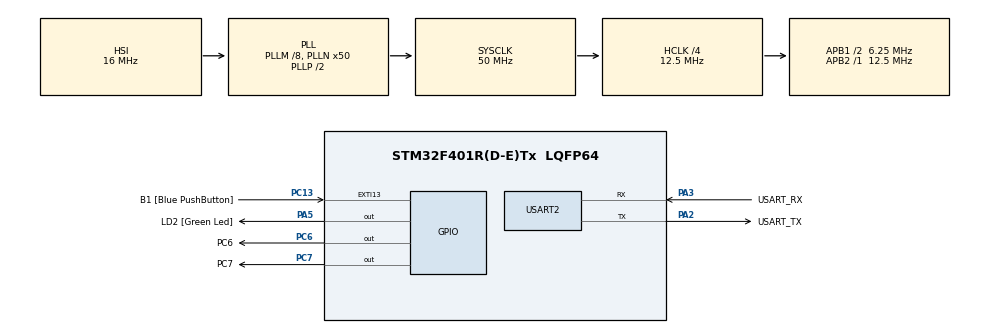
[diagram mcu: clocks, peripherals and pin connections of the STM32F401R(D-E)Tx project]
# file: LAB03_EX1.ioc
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Mcu.Family=STM32F4
Mcu.Name=STM32F401R(D-E)Tx
Mcu.Package=LQFP64
NVIC.PriorityGroup=NVIC_PRIORITYGROUP_0
PA13.GPIO_Label=TMS
PA13.Mode=Serial_Wire
PA13.Signal=SYS_JTMS-SWDIO
PA14.GPIO_Label=TCK
PA14.Mode=Serial_Wire
PA14.Signal=SYS_JTCK-SWCLK
PA2.GPIO_Label=USART_TX
PA2.GPIO_Mode=GPIO_MODE_AF_PP
PA2.GPIO_PuPd=GPIO_NOPULL
PA2.GPIO_Speed=GPIO_SPEED_FREQ_LOW
PA2.Mode=Asynchronous
PA2.Signal=USART2_TX
PA3.GPIO_Label=USART_RX
PA3.GPIO_Mode=GPIO_MODE_AF_PP
PA3.GPIO_PuPd=GPIO_NOPULL
PA3.GPIO_Speed=GPIO_SPEED_FREQ_LOW
PA3.Mode=Asynchronous
PA3.Signal=USART2_RX
PA5.GPIO_Label=LD2 [Green Led]
PA5.GPIO_Mode=GPIO_MODE_OUTPUT_PP
PA5.GPIO_PuPd=GPIO_NOPULL
PA5.GPIO_Speed=GPIO_SPEED_FREQ_LOW
PA5.Signal=GPIO_Output
PB3.GPIO_Label=SWO
PB3.Signal=SYS_JTDO-SWO
PC13-ANTI_TAMP.GPIO_Label=B1 [Blue PushButton]
PC13-ANTI_TAMP.GPIO_ModeDefaultEXTI=GPIO_MODE_IT_FALLING
PC13-ANTI_TAMP.GPIO_PuPd=GPIO_NOPULL
PC13-ANTI_TAMP.Signal=GPXTI13
PC14-OSC32_IN.Mode=LSE-External-Oscillator
PC14-OSC32_IN.Signal=RCC_OSC32_IN
PC15-OSC32_OUT.Mode=LSE-External-Oscillator
PC15-OSC32_OUT.Signal=RCC_OSC32_OUT
PC6.GPIO_Label=PC6
PC6.Signal=GPIO_Output
PC7.GPIO_Label=PC7
PC7.Signal=GPIO_Output
PH0\ -\ OSC_IN.Mode=HSE-External-Clock-Source
PH0\ -\ OSC_IN.Signal=RCC_OSC_IN
PH1\ -\ OSC_OUT.Mode=HSE-External-Clock-Source
PH1\ -\ OSC_OUT.Signal=RCC_OSC_OUT
ProjectManager.HeapSize=0x200
ProjectManager.StackSize=0x400
ProjectManager.TargetToolchain=STM32CubeIDE
RCC.48MHZClocksFreq_Value=14285714.285714285
RCC.AHBCLKDivider=RCC_SYSCLK_DIV4
RCC.AHBFreq_Value=12500000
RCC.APB1CLKDivider=RCC_HCLK_DIV2
RCC.APB1Freq_Value=6250000
RCC.APB1TimFreq_Value=12500000
RCC.APB2Freq_Value=12500000
RCC.APB2TimFreq_Value=12500000
RCC.CortexFreq_Value=12500000
RCC.HCLKFreq_Value=12500000
RCC.HSE_VALUE=8000000
RCC.HSI_VALUE=16000000
RCC.PLLM=8
RCC.PLLN=50
RCC.PLLQ=7
RCC.SYSCLKFreq_VALUE=50000000
RCC.SYSCLKSource=RCC_SYSCLKSOURCE_PLLCLK
RCC.VCOOutputFreq_Value=100000000
TIM3.Channel-Output\ Compare1\ No\ Output=TIM_CHANNEL_1
TIM3.Channel-Output\ Compare2\ No\ Output=TIM_CHANNEL_2
TIM3.Period=2499
USART2.VirtualMode=VM_ASYNC
VP_TIM3_VS_ClockSourceINT.Mode=Internal
VP_TIM3_VS_no_output1.Mode=Output Compare1 No Output
VP_TIM3_VS_no_output2.Mode=Output Compare2 No Output
board=NUCLEO-F401RE

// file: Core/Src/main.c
/* USER CODE BEGIN Header */
/**
  ******************************************************************************
  * @file           : main.c
  * @brief          : Main program body
  ******************************************************************************
  * @attention
  *
  * Copyright (c) 2023 STMicroelectronics.
  * All rights reserved.
  *
  * This software is licensed under terms that can be found in the LICENSE file
  * in the root directory of this software component.
  * If no LICENSE file comes with this software, it is provided AS-IS.
  *
  ******************************************************************************
  */
/* USER CODE END Header */
#include "main.h"

TIM_HandleTypeDef htim3;

UART_HandleTypeDef huart2;

void SystemClock_Config(void);
static void MX_GPIO_Init(void);
static void MX_USART2_UART_Init(void);
static void MX_TIM3_Init(void);

int main(void)
{

  /* MCU Configuration--------------------------------------------------------*/

  /* Reset of all peripherals, Initializes the Flash interface and the Systick. */
  HAL_Init();

  /* Configure the system clock */
  SystemClock_Config();

  /* Initialize all configured peripherals */
  MX_GPIO_Init();
  MX_USART2_UART_Init();
  MX_TIM3_Init();
  /* USER CODE BEGIN 2 */

  __HAL_TIM_SET_COMPARE(&htim3, TIM_CHANNEL_1, 250); //Sets the compare value for channel 1

  __HAL_TIM_SET_COMPARE(&htim3, TIM_CHANNEL_2, 400); //Sets the compare value for channel 2

  /* USER CODE END 2 */

  /* Infinite loop */
  /* USER CODE BEGIN WHILE */
  HAL_TIM_OC_Start(&htim3, TIM_CHANNEL_1); // Start the timer 3 in OC mode and activate channel 1
  HAL_TIM_OC_Start(&htim3, TIM_CHANNEL_2);// Start the timer 3 in OC mode and activate channel 2
  while (1)
  {

	  if(__HAL_TIM_GET_FLAG(&htim3, TIM_FLAG_CC2)){  // If the interrupt flag for channel 2 of tim3 is raised, then do:
		  __HAL_TIM_CLEAR_FLAG(&htim3, TIM_FLAG_CC2); // clear the interrupt flag
		  // We want the compare value of channel 2 to be 5 numbers equally spaced between 1 and 2499
		    // 400; 900; 1400; 1900 and 2400
		  __HAL_TIM_SET_COMPARE(&htim3, TIM_CHANNEL_2, (__HAL_TIM_GET_COMPARE(&htim3, TIM_CHANNEL_2) + 500) % 2500); // Update the compare value of channel 2
		  HAL_GPIO_TogglePin(PC7_GPIO_Port, PC7_Pin); // Toggle the pin PA10

	  }

	  if(__HAL_TIM_GET_FLAG(&htim3, TIM_FLAG_CC1)){ // If the interrupt flag for channel 1 of tim3 is raised, then do:
		  __HAL_TIM_CLEAR_FLAG(&htim3, TIM_FLAG_CC1); // clear the interrupt flag
		  HAL_GPIO_TogglePin(PC6_GPIO_Port, PC6_Pin); // Toggle the pin
	  	  }

	  if(__HAL_TIM_GET_FLAG(&htim3, TIM_FLAG_UPDATE)){ //If the update flag is raised, then
		  __HAL_TIM_CLEAR_FLAG(&htim3, TIM_FLAG_UPDATE);  // Clear the update flag
	  }
	  // The channel 1 generates of 2.5 KHz without the need of updating its compare value.
	  // This was done by choosing the appropriate values for the internal clock and the ARR
	  // Thus, to have a 12.5 KHz wave in channel 2, it should be enough to have the compare value matching the timer counter 5 times between 0 and the Auto Reload (with regular intervals).

	 //__HAL_DBGMCU_FREEZE_TIM3() //Freezes the timer for debugging
    /* USER CODE END WHILE */

  }
}

void SystemClock_Config(void)
{
  RCC_OscInitTypeDef RCC_OscInitStruct = {0};
  RCC_ClkInitTypeDef RCC_ClkInitStruct = {0};

  /** Configure the main internal regulator output voltage
  */
  __HAL_RCC_PWR_CLK_ENABLE();
  __HAL_PWR_VOLTAGESCALING_CONFIG(PWR_REGULATOR_VOLTAGE_SCALE2);

  /** Initializes the RCC Oscillators according to the specified parameters
  * in the RCC_OscInitTypeDef structure.
  */
  RCC_OscInitStruct.OscillatorType = RCC_OSCILLATORTYPE_HSI;
  RCC_OscInitStruct.HSIState = RCC_HSI_ON;
  RCC_OscInitStruct.HSICalibrationValue = RCC_HSICALIBRATION_DEFAULT;
  RCC_OscInitStruct.PLL.PLLState = RCC_PLL_ON;
  RCC_OscInitStruct.PLL.PLLSource = RCC_PLLSOURCE_HSI;
  RCC_OscInitStruct.PLL.PLLM = 8;
  RCC_OscInitStruct.PLL.PLLN = 50;
  RCC_OscInitStruct.PLL.PLLP = RCC_PLLP_DIV2;
  RCC_OscInitStruct.PLL.PLLQ = 7;
  if (HAL_RCC_OscConfig(&RCC_OscInitStruct) != HAL_OK)
  {
    Error_Handler();
  }

  /** Initializes the CPU, AHB and APB buses clocks
  */
  RCC_ClkInitStruct.ClockType = RCC_CLOCKTYPE_HCLK|RCC_CLOCKTYPE_SYSCLK
                              |RCC_CLOCKTYPE_PCLK1|RCC_CLOCKTYPE_PCLK2;
  RCC_ClkInitStruct.SYSCLKSource = RCC_SYSCLKSOURCE_PLLCLK;
  RCC_ClkInitStruct.AHBCLKDivider = RCC_SYSCLK_DIV4;
  RCC_ClkInitStruct.APB1CLKDivider = RCC_HCLK_DIV2;
  RCC_ClkInitStruct.APB2CLKDivider = RCC_HCLK_DIV1;

  if (HAL_RCC_ClockConfig(&RCC_ClkInitStruct, FLASH_LATENCY_0) != HAL_OK)
  {
    Error_Handler();
  }
}

static void MX_TIM3_Init(void)
{

  TIM_ClockConfigTypeDef sClockSourceConfig = {0};
  TIM_MasterConfigTypeDef sMasterConfig = {0};
  TIM_OC_InitTypeDef sConfigOC = {0};

  htim3.Instance = TIM3;
  htim3.Init.Prescaler = 0;
  htim3.Init.CounterMode = TIM_COUNTERMODE_UP;
  htim3.Init.Period = 2499;
  htim3.Init.ClockDivision = TIM_CLOCKDIVISION_DIV1;
  htim3.Init.AutoReloadPreload = TIM_AUTORELOAD_PRELOAD_DISABLE;
  if (HAL_TIM_Base_Init(&htim3) != HAL_OK)
  {
    Error_Handler();
  }
  sClockSourceConfig.ClockSource = TIM_CLOCKSOURCE_INTERNAL;
  if (HAL_TIM_ConfigClockSource(&htim3, &sClockSourceConfig) != HAL_OK)
  {
    Error_Handler();
  }
  if (HAL_TIM_OC_Init(&htim3) != HAL_OK)
  {
    Error_Handler();
  }
  sMasterConfig.MasterOutputTrigger = TIM_TRGO_RESET;
  sMasterConfig.MasterSlaveMode = TIM_MASTERSLAVEMODE_DISABLE;
  if (HAL_TIMEx_MasterConfigSynchronization(&htim3, &sMasterConfig) != HAL_OK)
  {
    Error_Handler();
  }
  sConfigOC.OCMode = TIM_OCMODE_TIMING;
  sConfigOC.Pulse = 0;
  sConfigOC.OCPolarity = TIM_OCPOLARITY_HIGH;
  sConfigOC.OCFastMode = TIM_OCFAST_DISABLE;
  if (HAL_TIM_OC_ConfigChannel(&htim3, &sConfigOC, TIM_CHANNEL_1) != HAL_OK)
  {
    Error_Handler();
  }
  if (HAL_TIM_OC_ConfigChannel(&htim3, &sConfigOC, TIM_CHANNEL_2) != HAL_OK)
  {
    Error_Handler();
  }

}

static void MX_USART2_UART_Init(void)
{

  huart2.Instance = USART2;
  huart2.Init.BaudRate = 115200;
  huart2.Init.WordLength = UART_WORDLENGTH_8B;
  huart2.Init.StopBits = UART_STOPBITS_1;
  huart2.Init.Parity = UART_PARITY_NONE;
  huart2.Init.Mode = UART_MODE_TX_RX;
  huart2.Init.HwFlowCtl = UART_HWCONTROL_NONE;
  huart2.Init.OverSampling = UART_OVERSAMPLING_16;
  if (HAL_UART_Init(&huart2) != HAL_OK)
  {
    Error_Handler();
  }

}

static void MX_GPIO_Init(void)
{
  GPIO_InitTypeDef GPIO_InitStruct = {0};

  /* GPIO Ports Clock Enable */
  __HAL_RCC_GPIOC_CLK_ENABLE();
  __HAL_RCC_GPIOH_CLK_ENABLE();
  __HAL_RCC_GPIOA_CLK_ENABLE();
  __HAL_RCC_GPIOB_CLK_ENABLE();

  /*Configure GPIO pin Output Level */
  HAL_GPIO_WritePin(LD2_GPIO_Port, LD2_Pin, GPIO_PIN_RESET);

  /*Configure GPIO pin Output Level */
  HAL_GPIO_WritePin(GPIOC, PC6_Pin|PC7_Pin, GPIO_PIN_RESET);

  /*Configure GPIO pin : B1_Pin */
  GPIO_InitStruct.Pin = B1_Pin;
  GPIO_InitStruct.Mode = GPIO_MODE_IT_FALLING;
  GPIO_InitStruct.Pull = GPIO_NOPULL;
  HAL_GPIO_Init(B1_GPIO_Port, &GPIO_InitStruct);

  /*Configure GPIO pin : LD2_Pin */
  GPIO_InitStruct.Pin = LD2_Pin;
  GPIO_InitStruct.Mode = GPIO_MODE_OUTPUT_PP;
  GPIO_InitStruct.Pull = GPIO_NOPULL;
  GPIO_InitStruct.Speed = GPIO_SPEED_FREQ_LOW;
  HAL_GPIO_Init(LD2_GPIO_Port, &GPIO_InitStruct);

  /*Configure GPIO pins : PC6_Pin PC7_Pin */
  GPIO_InitStruct.Pin = PC6_Pin|PC7_Pin;
  GPIO_InitStruct.Mode = GPIO_MODE_OUTPUT_PP;
  GPIO_InitStruct.Pull = GPIO_NOPULL;
  GPIO_InitStruct.Speed = GPIO_SPEED_FREQ_LOW;
  HAL_GPIO_Init(GPIOC, &GPIO_InitStruct);

}

void Error_Handler(void)
{
  __disable_irq();
  while (1)
  {
  }
}
